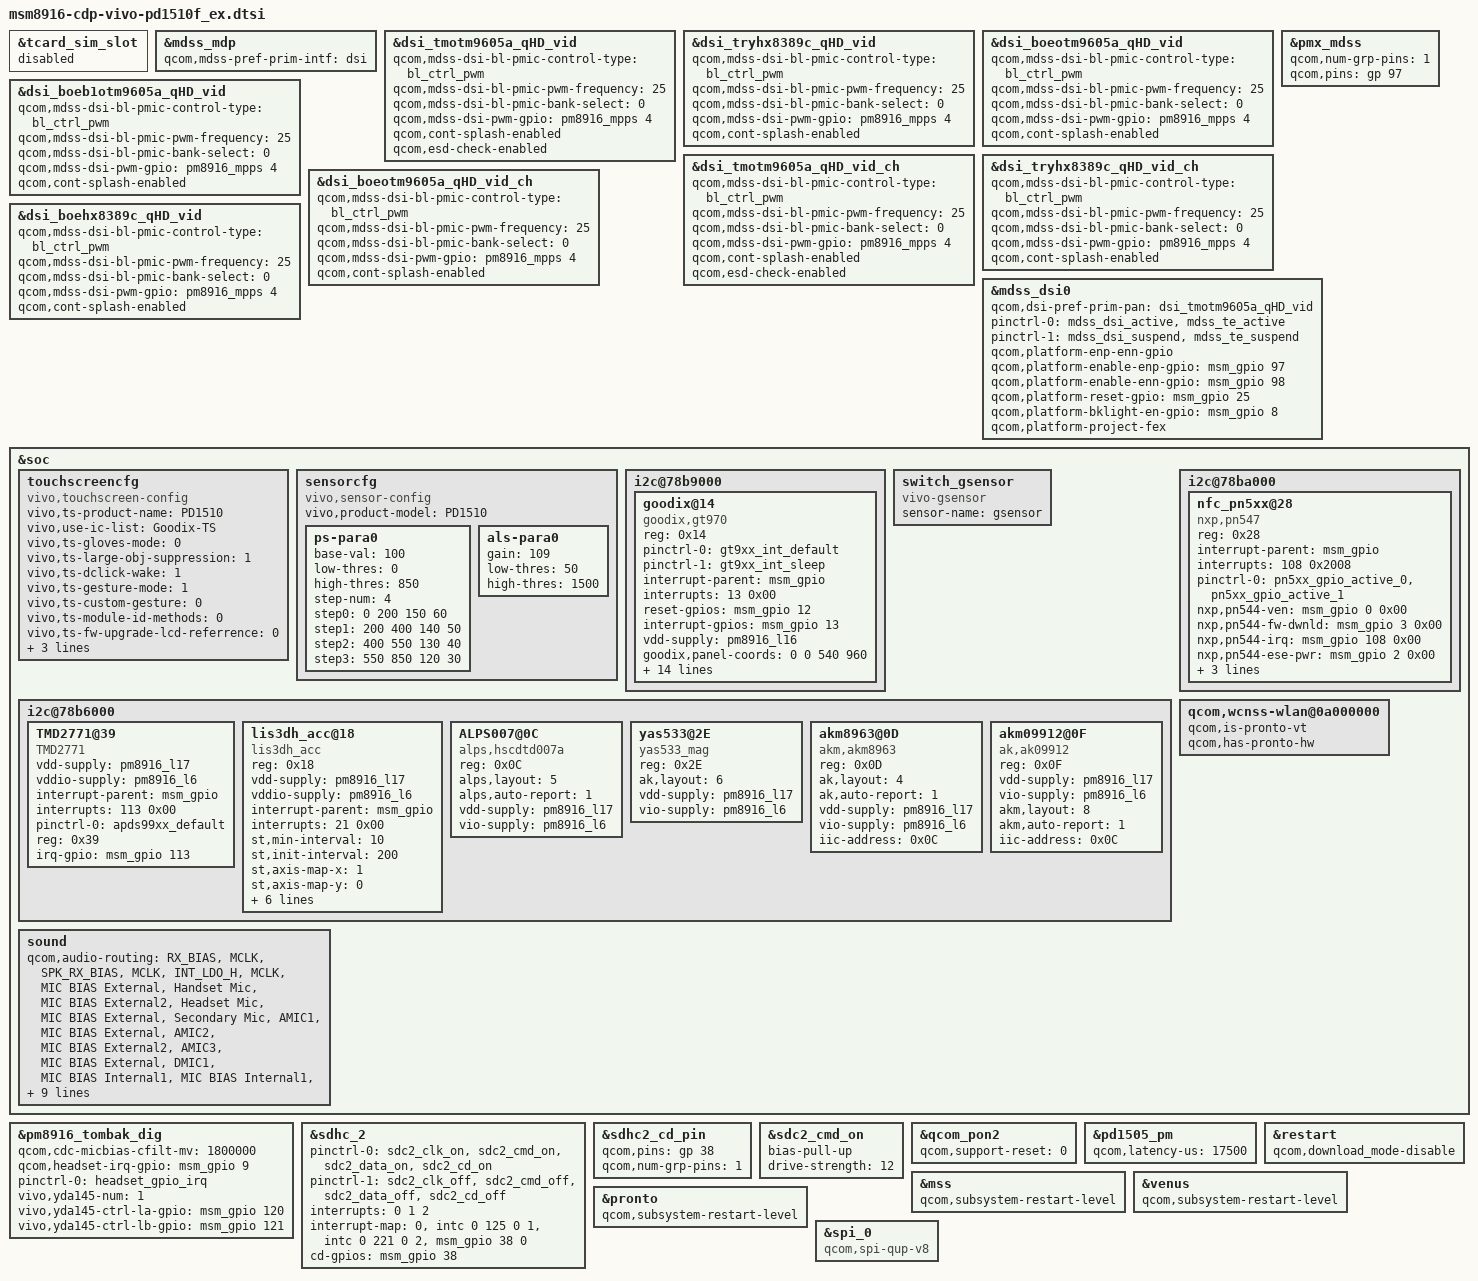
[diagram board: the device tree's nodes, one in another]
/* Copyright (c) 2014-2015, The Linux Foundation. All rights reserved.
 *
 * This program is free software; you can redistribute it and/or modify
 * it under the terms of the GNU General Public License version 2 and
 * only version 2 as published by the Free Software Foundation.
 *
 * This program is distributed in the hope that it will be useful,
 * but WITHOUT ANY WARRANTY; without even the implied warranty of
 * MERCHANTABILITY or FITNESS FOR A PARTICULAR PURPOSE.  See the
 * GNU General Public License for more details.
 */
 
#include "dsi-panel-tmotm9605a-qhd-cmd.dtsi"
#include "dsi-trypanel-hx8389c-qhd-video.dtsi"
#include "dsi-panel-boeotm9605a-qhd-cmd.dtsi"
#include "dsi-panel-tmotm9605a-qhd-cmd-ch.dtsi"
#include "dsi-trypanel-hx8389c-qhd-video-ch.dtsi"
#include "dsi-panel-boeotm9605a-qhd-cmd-ch.dtsi"
#include "dsi-boepanel-hx8389c-qhd-video.dtsi"
#include "dsi-panel-boeb1otm9605a-qhd-cmd.dtsi"
#include "msm8916-camera-sensor-cdp-vivo-pd1510f_ex.dtsi"

&tcard_sim_slot {
	status = "disabled";
};

&mdss_mdp {
	qcom,mdss-pref-prim-intf = "dsi";
};

&dsi_tmotm9605a_qHD_vid{
	qcom,mdss-dsi-bl-pmic-control-type = "bl_ctrl_pwm";
	qcom,mdss-dsi-bl-pmic-pwm-frequency = <25>;
	qcom,mdss-dsi-bl-pmic-bank-select = <0>;
	qcom,mdss-dsi-pwm-gpio = <&pm8916_mpps 4 0>;
	qcom,cont-splash-enabled;
	qcom,esd-check-enabled;
};

&dsi_tryhx8389c_qHD_vid{
	qcom,mdss-dsi-bl-pmic-control-type = "bl_ctrl_pwm";
	qcom,mdss-dsi-bl-pmic-pwm-frequency = <25>;
	qcom,mdss-dsi-bl-pmic-bank-select = <0>;
	qcom,mdss-dsi-pwm-gpio = <&pm8916_mpps 4 0>;
	qcom,cont-splash-enabled;
	//qcom,esd-check-enabled;
};

&dsi_boeotm9605a_qHD_vid{
	qcom,mdss-dsi-bl-pmic-control-type = "bl_ctrl_pwm";
	qcom,mdss-dsi-bl-pmic-pwm-frequency = <25>;
	qcom,mdss-dsi-bl-pmic-bank-select = <0>;
	qcom,mdss-dsi-pwm-gpio = <&pm8916_mpps 4 0>;
	qcom,cont-splash-enabled;
	//qcom,esd-check-enabled;
};

&dsi_boeb1otm9605a_qHD_vid{
	qcom,mdss-dsi-bl-pmic-control-type = "bl_ctrl_pwm";
	qcom,mdss-dsi-bl-pmic-pwm-frequency = <25>;
	qcom,mdss-dsi-bl-pmic-bank-select = <0>;
	qcom,mdss-dsi-pwm-gpio = <&pm8916_mpps 4 0>;
	qcom,cont-splash-enabled;
	//qcom,esd-check-enabled;
};

&dsi_tmotm9605a_qHD_vid_ch{
	qcom,mdss-dsi-bl-pmic-control-type = "bl_ctrl_pwm";
	qcom,mdss-dsi-bl-pmic-pwm-frequency = <25>;
	qcom,mdss-dsi-bl-pmic-bank-select = <0>;
	qcom,mdss-dsi-pwm-gpio = <&pm8916_mpps 4 0>;
	qcom,cont-splash-enabled;
	qcom,esd-check-enabled;
};

&dsi_tryhx8389c_qHD_vid_ch{
	qcom,mdss-dsi-bl-pmic-control-type = "bl_ctrl_pwm";
	qcom,mdss-dsi-bl-pmic-pwm-frequency = <25>;
	qcom,mdss-dsi-bl-pmic-bank-select = <0>;
	qcom,mdss-dsi-pwm-gpio = <&pm8916_mpps 4 0>;
	qcom,cont-splash-enabled;
	//qcom,esd-check-enabled;
};

&dsi_boeotm9605a_qHD_vid_ch{
	qcom,mdss-dsi-bl-pmic-control-type = "bl_ctrl_pwm";
	qcom,mdss-dsi-bl-pmic-pwm-frequency = <25>;
	qcom,mdss-dsi-bl-pmic-bank-select = <0>;
	qcom,mdss-dsi-pwm-gpio = <&pm8916_mpps 4 0>;
	qcom,cont-splash-enabled;
	//qcom,esd-check-enabled;
};

&dsi_boehx8389c_qHD_vid{
	qcom,mdss-dsi-bl-pmic-control-type = "bl_ctrl_pwm";
	qcom,mdss-dsi-bl-pmic-pwm-frequency = <25>;
	qcom,mdss-dsi-bl-pmic-bank-select = <0>;
	qcom,mdss-dsi-pwm-gpio = <&pm8916_mpps 4 0>;
	qcom,cont-splash-enabled;
	//qcom,esd-check-enabled;
};

&pmx_mdss {
	qcom,num-grp-pins = <1>;
	//qcom,pins = <&gp 97>, <&gp 25>, <&gp 98>, <&gp 08>;
	qcom,pins = <&gp 97>;
};
/*
&pmx_mdss_te {
	qcom,num-grp-pins = <1>;
	qcom,pins = <&gp 24>;
};
*/
&mdss_dsi0 {
	qcom,dsi-pref-prim-pan = <&dsi_tmotm9605a_qHD_vid>;
	pinctrl-names = "mdss_default", "mdss_sleep";
	pinctrl-0 = <&mdss_dsi_active &mdss_te_active>;
	pinctrl-1 = <&mdss_dsi_suspend &mdss_te_suspend>;

	qcom,platform-enp-enn-gpio;
	qcom,platform-enable-enp-gpio = <&msm_gpio 97 0>;
	qcom,platform-enable-enn-gpio = <&msm_gpio 98 0>;
	qcom,platform-reset-gpio = <&msm_gpio 25 0>;
	qcom,platform-bklight-en-gpio = <&msm_gpio 8 0>;
	qcom,platform-project-fex;
};


&soc {
	touchscreencfg { /* vivo ts configure */
	   compatible = "vivo,touchscreen-config";
	   vivo,ts-product-name="PD1510";
	   vivo,use-ic-list="Goodix-TS";
	   
	   /*----- function set BEG ---- */
	   vivo,ts-gloves-mode=<0>;
	   vivo,ts-large-obj-suppression=<1>;
	   vivo,ts-dclick-wake=<1>;
	   vivo,ts-gesture-mode=<1>; /*1=sold in native,2=sold in abroad,3...etc=for custom extensive*/
	   vivo,ts-custom-gesture=<0>;
	   vivo,ts-module-id-methods=<0>;/*0=by IC id,1=gpio,2=by LCD ID 3=...etc=for custom extensive*/
	   vivo,ts-fw-upgrade-lcd-referrence=<0>;
	   vivo,ts-anti-esd=<1>;
	   vivo,ts-charger-conn-judge=<1>;
	   vivo,ts-module-smt-mode=<1>; /* 0=COB,1=COF */
	   /*----- function set END ---- */

	};
	
	sensorcfg {
		compatible = "vivo,sensor-config";
		vivo,product-model = "PD1510";
		ps-para0 {
			base-val = <100>;
			low-thres = <0>;
			high-thres = <850>;
			step-num = <4>;
			step0 = <  0 200 150 60>;
			step1 = <200 400 140 50>;
			step2 = <400 550 130 40>;
			step3 = <550 850 120 30>;
		};
		
		als-para0 {
			gain = <109>;
			low-thres = <50>;
			high-thres = <1500>;
		};
	};
	
	i2c@78b9000 { /* BLSP1 QUP5 */
		goodix@14 { //gt915L
			compatible = "goodix,gt970";
			reg = <0x14>;
			/* pins used by touchscreen */
			pinctrl-names = "gt9xx_int_default","gt9xx_int_suspend";
            		pinctrl-0 = <&gt9xx_int_default>;
            		pinctrl-1 = <&gt9xx_int_sleep>;
			interrupt-parent = <&msm_gpio>;
			interrupts = <13 0x00>;
			reset-gpios = <&msm_gpio 12 0x00>;
			interrupt-gpios = <&msm_gpio 13 0x00>;
            //vcc_i2c-supply = <&pm8916_l6>;
            vdd-supply = <&pm8916_l16>;/* <&tp_power>;*/
			goodix,panel-coords = <0 0 540 960>;
			goodix,display-coords = <0 0 540 960>;
			goodix,button-map= <158 102 139>;
			goodix,family-id = <0x0>;
            goodix,i2c-pull-up;
			goodix,cfg-data0 =    //Biel
			[
				47 1C 02 07 04 0A 34 10 01 08 
				32 08 4B 32 33 35 00 00 37 13
				00 10 00 14 14 26 14 8C 2C 0D
				46 48 D3 07 D3 07 00 99 33 11
				00 00 00 00 00 00 00 08 0A A0 
				21 28 5F 94 D0 02 3C 1E 00 04
				D0 2B 00 B1 34 1E 9C 3D 00 88
				49 00 78 57 00 78 00 00 00 00 
				00 00 00 00 00 00 00 00 00 00
				00 00 00 00 F7 01 00 00 00 00
				00 00 00 00 00 14 50 00 00 00
				00 1E 1A 18 16 14 12 10 0E 0C
				0A 08 06 04 02 FF 00 00 00 00 
				00 00 00 00 08 00 00 00 DE 00
				00 41 16 18 1C 1D 1E 1F 20 21 
				22 24 26 28 14 13 12 10 0F 0C 
				0A 08 06 04 02 00 FF FF 00 00
				00 00 00 00 00 00 00 00 00 00
				00 00 00 00 1E 01
			];    
			
			goodix,cfg-data2 =    //Truly
			[
				47 1C 02 07 04 0A 34 10 01 08 
				32 08 4B 32 33 35 00 00 37 13
				00 10 00 14 14 26 14 8C 2C 0D
				46 48 D3 07 D3 07 00 99 33 11
				00 00 00 00 00 00 00 08 0A A0 
				21 28 5F 94 D0 02 3C 1E 00 04
				D0 2B 00 B1 34 1E 9C 3D 00 88
				49 00 78 57 00 78 00 00 00 00 
				00 00 00 00 00 00 00 00 00 00
				00 00 00 00 F7 01 00 00 00 00
				00 00 00 00 00 14 50 00 00 00
				00 1E 1A 18 16 14 12 10 0E 0C
				0A 08 06 04 02 FF 00 00 00 00 
				00 00 00 00 08 00 00 00 DE 00
				00 41 16 18 1C 1D 1E 1F 20 21 
				22 24 26 28 14 13 12 10 0F 0C 
				0A 08 06 04 02 00 FF FF 00 00
				00 00 00 00 00 00 00 00 00 00
				00 00 00 00 1E 01
			]; 
			
			goodix,cfg-data3 =    //Yeji
			[
				47 1C 02 07 04 0A 34 10 01 08 
				32 08 4B 32 33 35 00 00 37 13
				00 10 00 14 14 26 14 8C 2C 0D
				46 48 D3 07 D3 07 00 99 33 11
				00 00 00 00 00 00 00 08 0A A0 
				21 28 5F 94 D0 02 3C 1E 00 04
				D0 2B 00 B1 34 1E 9C 3D 00 88
				49 00 78 57 00 78 00 00 00 00 
				00 00 00 00 00 00 00 00 00 00
				00 00 00 00 F7 01 00 00 00 00
				00 00 00 00 00 14 50 00 00 00
				00 1E 1A 18 16 14 12 10 0E 0C
				0A 08 06 04 02 FF 00 00 00 00 
				00 00 00 00 08 00 00 00 DE 00
				00 41 16 18 1C 1D 1E 1F 20 21 
				22 24 26 28 14 13 12 10 0F 0C 
				0A 08 06 04 02 00 FF FF 00 00
				00 00 00 00 00 00 00 00 00 00
				00 00 00 00 1E 01
		      ];                                  
				
			ts-suspend-resume=<0>;
			ts-fixed-key-type=<1>; /*0=0d,1=2d */
			
			/*--virtualkeys: EV_KEY:KEY_MENU:cx:cy:w:h:EV_KEY:KEY_HOMEPAGE:cx:cy:w:h:EV_KEY:KEY_BACK:cx:cy:w:h--*/
			ts-virt-key="0x01:139:90:1028:120:90:0x01:251:181:1028:62:90:0x01:172:272:1028:120:90:0x01:251:368:1028:72:90:0x01:158:464:1028:120:90";
		};
	
	};
	switch_gsensor {
		  compatible = "vivo-gsensor";
		  sensor-name = "gsensor";
		/*  sensor,gpio-irq = <&msm_gpio 21 0x00>;  */
	  };
	i2c@78b6000 { /* BLSP1 QUP2 */ 	
		TMD2771@39 {
			compatible = "TMD2771";
			vdd-supply = <&pm8916_l17>;
			vddio-supply = <&pm8916_l6>;
			interrupt-parent = <&msm_gpio>;
			interrupts = <113 0x00>;
			pinctrl-names = "default";
			pinctrl-0 = <&apds99xx_default>;
			reg = <0x39>;
			irq-gpio = <&msm_gpio 113 0x00>;
		};
		lis3dh_acc@18 {
			compatible = "lis3dh_acc";
			reg = <0x18>;
			vdd-supply = <&pm8916_l17>;
			vddio-supply = <&pm8916_l6>;
			interrupt-parent = <&msm_gpio>;
			interrupts = <21 0x00>;
			st,min-interval = <10>;
			st,init-interval = <200>;
			st,axis-map-x = <1>;
			st,axis-map-y = <0>;
			st,axis-map-z = <2>;
			st,g-range = <2>;
			st,negate-x = <0>;
			st,negate-y = <1>;
			st,negate-z = <0>;
			sensor,gpio-irq = <&msm_gpio 21 0x00>;
		};
		ALPS007@0C {
    		compatible = "alps,hscdtd007a";
    		reg = <0x0C>;
    		alps,layout =<5>;
    		alps,auto-report=<1>;
    		vdd-supply = <&pm8916_l17>;
    		vio-supply = <&pm8916_l6>;
    		};
		yas533@2E {
			compatible = "yas533_mag";
			reg = <0x2E>;
			ak,layout =<6>;
			vdd-supply = <&pm8916_l17>;
			vio-supply = <&pm8916_l6>;
		};
		akm8963@0D {
			compatible = "akm,akm8963";
			reg = <0x0D>;
			ak,layout =<4>;
			ak,auto-report=<1>;
			vdd-supply = <&pm8916_l17>;
			vio-supply = <&pm8916_l6>;
			iic-address=<0x0C>;
		};
		akm09912@0F{
		    compatible = "ak,ak09912";
		    reg = <0x0F>;
		    vdd-supply = <&pm8916_l17>;
		    vio-supply = <&pm8916_l6>;
		    akm,layout = <8>;
		    akm,auto-report=<1>;
		    iic-address=<0x0C>;
	    };
	};

	/* VIVO_NFC */
	i2c@78ba000 { /* BLSP1 QUP6 */
		status = "okay";
		nfc_pn5xx@28 {
			compatible = "nxp,pn547";
			reg = <0x28>;
			interrupt-parent = <&msm_gpio>;
			interrupts = <108 0x2008>;
			pinctrl-names = "default";
			pinctrl-0 = <&pn5xx_gpio_active_0 &pn5xx_gpio_active_1>;
			nxp,pn544-ven = <&msm_gpio 0 0x00>;
			nxp,pn544-fw-dwnld = <&msm_gpio 3 0x00>;
			nxp,pn544-irq = <&msm_gpio 108 0x00>;
			nxp,pn544-ese-pwr = <&msm_gpio 2 0x00>;
			nxp,pn5xx-clkreq = <&pm8916_gpios 2 0x00>;
			nxp,pn5xx-pvdden_gpio = <&msm_gpio 118 0x00>;
			clock-names = "ref_clk";
			clocks = <&clock_rpm clk_bb_clk2_pin>;
		};
	};

	qcom,wcnss-wlan@0a000000 {
	    /* qcom,has-autodetect-xo; */ 
		 qcom,is-pronto-vt;   
		 qcom,has-pronto-hw;  
	};	

	sound {
		qcom,audio-routing =
			"RX_BIAS", "MCLK",
			"SPK_RX_BIAS", "MCLK",
			"INT_LDO_H", "MCLK",
			"MIC BIAS External", "Handset Mic",
			"MIC BIAS External2", "Headset Mic",
			"MIC BIAS External", "Secondary Mic",
			"AMIC1", "MIC BIAS External",
			"AMIC2", "MIC BIAS External2",
			"AMIC3", "MIC BIAS External",
			"DMIC1", "MIC BIAS Internal1",
			"MIC BIAS Internal1", "Digital Mic1",
			"DMIC2", "MIC BIAS Internal1",
			"MIC BIAS Internal1", "Digital Mic2",
			"KTV Handset Mic In", "MIC BIAS External",
			"KTV Headset Mic In", "MIC BIAS External2";
			pinctrl-names = "cdc_lines_act",
				"cdc_lines_sus";
			pinctrl-0 = <&cdc_pdm_lines_act>;
			pinctrl-1 = <&cdc_pdm_lines_sus>;
		vivo,fm-support;
		vivo,fm-pcm-hp = <5>;
		vivo,fm-pcm-spk = <5>;
	};
};
&pm8916_tombak_dig{
		qcom,cdc-micbias-cfilt-mv = <1800000>;
		qcom,headset-irq-gpio = <&msm_gpio 9 0>;
		pinctrl-names = "headset_gpio_irq";
		pinctrl-0 =  <&headset_gpio_irq>;
		vivo,yda145-num=<1>;
		vivo,yda145-ctrl-la-gpio=<&msm_gpio 120 0>;
		vivo,yda145-ctrl-lb-gpio=<&msm_gpio 121 0>;
};

&sdhc_2 {
	    pinctrl-names = "active", "sleep";
		pinctrl-0 = <&sdc2_clk_on &sdc2_cmd_on &sdc2_data_on &sdc2_cd_on>;
		pinctrl-1 = <&sdc2_clk_off &sdc2_cmd_off &sdc2_data_off &sdc2_cd_off>;
};
/*
&soc {
	tlmm_pinmux: pinctrl@1000000 {
		pmx_ts_id_active {
			qcom,pins = <&gp 0>,<&gp 3>;
			qcom,pin-func = <0>;
			qcom,num-grp-pins = <2>;
			label = "pmx_ts_id_active";

			ts_id_active: ts_id_active {
				drive-strength = <2>;
				bias-pull-up;
			};
		};

		pmx_ts_id_disactive {
			qcom,pins = <&gp 0>,<&gp 3>;
			qcom,pin-func = <0>;
			qcom,num-grp-pins = <2>;
			label = "pmx_ts_id_disactive";

			ts_id_disactive: ts_id_disactive {
				drive-strength = <2>;
				bias-pull-down;
			};
		};
	};
};
*/
&sdhc_2 {
    interrupts = <0 1 2>;
    interrupt-map = <0 &intc 0 125 0
			1 &intc 0 221 0
			2 &msm_gpio 38 0>;
    cd-gpios = <&msm_gpio 38 0x0>;
/*	cd-gpio-invert;*/
};

&sdhc2_cd_pin {
			qcom,pins = <&gp 38>;
			qcom,num-grp-pins = <1>;
};

&sdc2_cmd_on {
    bias-pull-up; /* pull up */
    drive-strength = <12>; /* 10 MA: change it to 12MA for certain SD card */
};

&qcom_pon2 {
		qcom,support-reset = <0>;
};

&pd1505_pm{
	qcom,latency-us = <17500>;
};

&restart {
	qcom,download_mode-disable;
};
&mss {
	qcom,subsystem-restart-level;
};
&venus {
	qcom,subsystem-restart-level;
};
&pronto {
	qcom,subsystem-restart-level;
};
&spi_0 {
	compatible = "qcom,spi-qup-v8";
};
